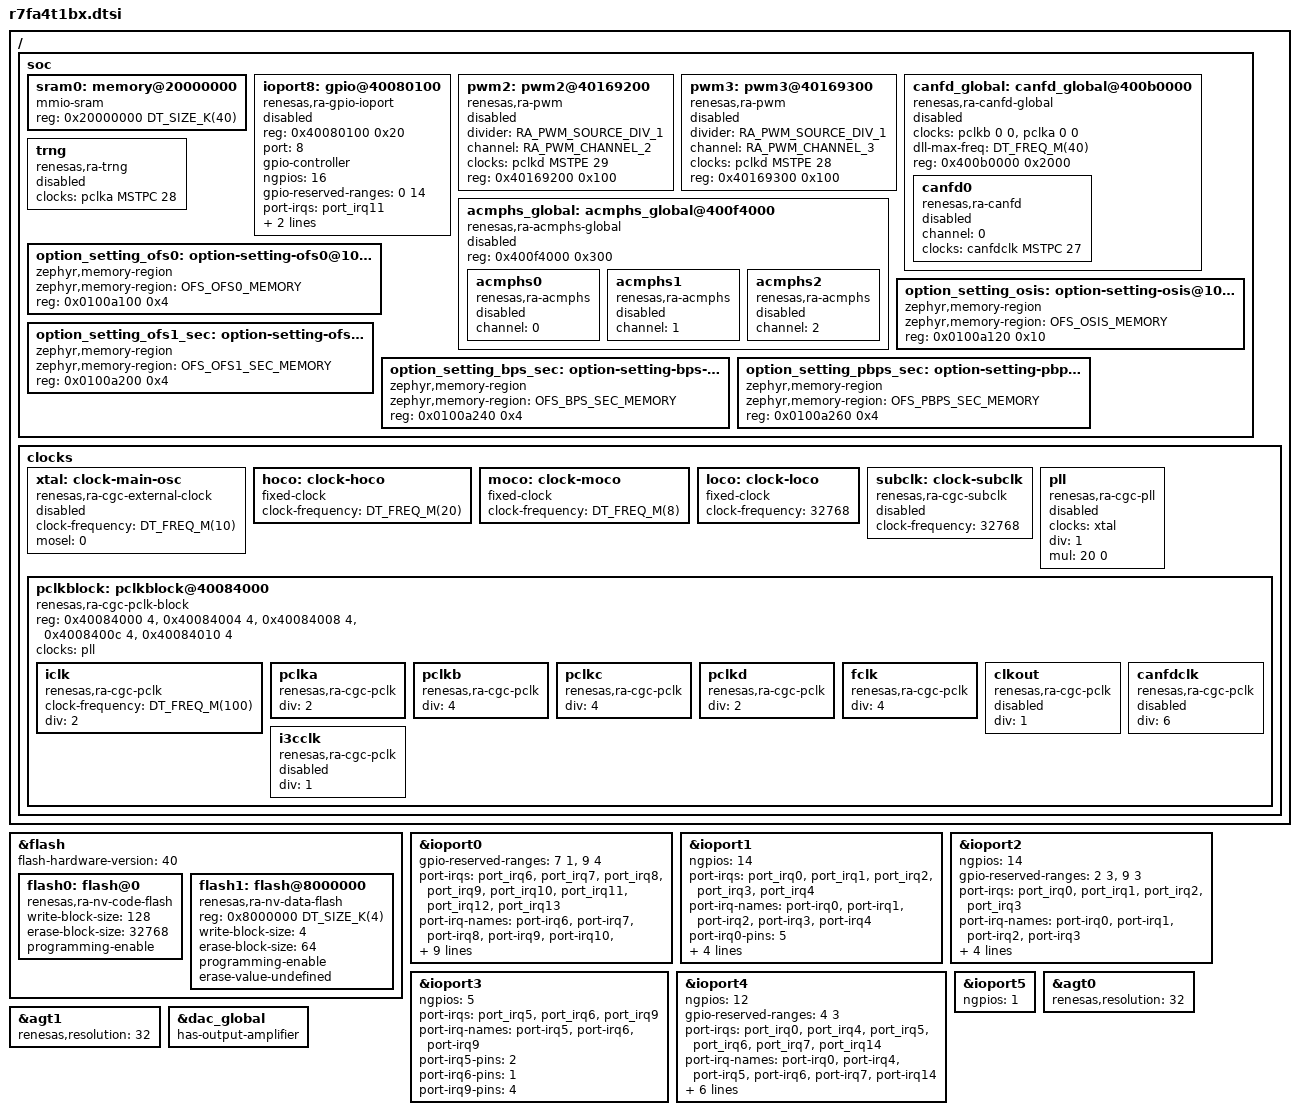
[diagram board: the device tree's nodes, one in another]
/*
 * Copyright (c) 2025 Renesas Electronics Corporation
 *
 * SPDX-License-Identifier: Apache-2.0
 */

#include <arm/renesas/ra/ra4/ra4-cm33-common.dtsi>
#include <zephyr/dt-bindings/misc/renesas/ra-elc/ra4t1-elc.h>

/delete-node/ &iic0;
/delete-node/ &iic1;
/delete-node/ &adc1;
/delete-node/ &agt2;
/delete-node/ &agt3;
/delete-node/ &agt4;
/delete-node/ &agt5;
/delete-node/ &usbfs;
/delete-node/ &usbfs_phy;

/ {
	soc {
		sram0: memory@20000000 {
			compatible = "mmio-sram";
			reg = <0x20000000 DT_SIZE_K(40)>;
		};

		ioport8: gpio@40080100 {
			compatible = "renesas,ra-gpio-ioport";
			reg = <0x40080100 0x20>;
			port = <8>;
			gpio-controller;
			#gpio-cells = <2>;
			ngpios = <16>;
			status = "disabled";
		};

		pwm2: pwm2@40169200 {
			compatible = "renesas,ra-pwm";
			divider = <RA_PWM_SOURCE_DIV_1>;
			channel = <RA_PWM_CHANNEL_2>;
			clocks = <&pclkd MSTPE 29>;
			reg = <0x40169200 0x100>;
			#pwm-cells = <3>;
			status = "disabled";
		};

		pwm3: pwm3@40169300 {
			compatible = "renesas,ra-pwm";
			divider = <RA_PWM_SOURCE_DIV_1>;
			channel = <RA_PWM_CHANNEL_3>;
			clocks = <&pclkd MSTPE 28>;
			reg = <0x40169300 0x100>;
			#pwm-cells = <3>;
			status = "disabled";
		};

		canfd_global: canfd_global@400b0000 {
			compatible = "renesas,ra-canfd-global";
			clocks = <&pclkb 0 0>, <&pclka 0 0>;
			clock-names = "opclk", "ramclk";
			dll-max-freq = <DT_FREQ_M(40)>;
			reg = <0x400b0000 0x2000>;
			status = "disabled";

			canfd0: canfd0 {
				compatible = "renesas,ra-canfd";
				channel = <0>;
				clocks = <&canfdclk MSTPC 27>;
				clock-names = "dllclk";
				status = "disabled";
			};
		};

		acmphs_global: acmphs_global@400f4000 {
			compatible = "renesas,ra-acmphs-global";
			reg = <0x400f4000 0x300>;
			status = "disabled";

			acmphs0: acmphs0 {
				compatible = "renesas,ra-acmphs";
				channel = <0>;
				status = "disabled";
			};

			acmphs1: acmphs1 {
				compatible = "renesas,ra-acmphs";
				channel = <1>;
				status = "disabled";
			};

			acmphs2: acmphs2 {
				compatible = "renesas,ra-acmphs";
				channel = <2>;
				status = "disabled";
			};
		};

		trng: trng {
			compatible = "renesas,ra-trng";
			clocks = <&pclka MSTPC 28>;
			status = "disabled";
		};

		option_setting_ofs0: option-setting-ofs0@100a100 {
			compatible = "zephyr,memory-region";
			zephyr,memory-region = "OFS_OFS0_MEMORY";
			reg = <0x0100a100 0x4>;
			status = "okay";
		};

		option_setting_osis: option-setting-osis@100a120 {
			compatible = "zephyr,memory-region";
			zephyr,memory-region = "OFS_OSIS_MEMORY";
			reg = <0x0100a120 0x10>;
			status = "okay";
		};

		option_setting_ofs1_sec: option-setting-ofs1-sec@100a200 {
			compatible = "zephyr,memory-region";
			zephyr,memory-region = "OFS_OFS1_SEC_MEMORY";
			reg = <0x0100a200 0x4>;
			status = "okay";
		};

		option_setting_bps_sec: option-setting-bps-sec@100a240 {
			compatible = "zephyr,memory-region";
			zephyr,memory-region = "OFS_BPS_SEC_MEMORY";
			reg = <0x0100a240 0x4>;
			status = "okay";
		};

		option_setting_pbps_sec: option-setting-pbps-sec@100a260 {
			compatible = "zephyr,memory-region";
			zephyr,memory-region = "OFS_PBPS_SEC_MEMORY";
			reg = <0x0100a260 0x4>;
			status = "okay";
		};
	};

	clocks: clocks {
		#address-cells = <1>;
		#size-cells = <1>;

		xtal: clock-main-osc {
			compatible = "renesas,ra-cgc-external-clock";
			clock-frequency = <DT_FREQ_M(10)>;
			#clock-cells = <0>;
			mosel = <0>;
			status = "disabled";
		};

		hoco: clock-hoco {
			compatible = "fixed-clock";
			clock-frequency = <DT_FREQ_M(20)>;
			#clock-cells = <0>;
		};

		moco: clock-moco {
			compatible = "fixed-clock";
			clock-frequency = <DT_FREQ_M(8)>;
			#clock-cells = <0>;
		};

		loco: clock-loco {
			compatible = "fixed-clock";
			clock-frequency = <32768>;
			#clock-cells = <0>;
		};

		subclk: clock-subclk {
			compatible = "renesas,ra-cgc-subclk";
			clock-frequency = <32768>;
			#clock-cells = <0>;
			status = "disabled";
		};

		pll: pll {
			compatible = "renesas,ra-cgc-pll";
			#clock-cells = <0>;

			/* PLL */
			clocks = <&xtal>;
			div = <1>;
			mul = <20 0>;
			status = "disabled";
		};

		pclkblock: pclkblock@40084000 {
			compatible = "renesas,ra-cgc-pclk-block";
			reg = <0x40084000 4>, <0x40084004 4>, <0x40084008 4>,
			      <0x4008400c 4>, <0x40084010 4>;
			reg-names = "MSTPA", "MSTPB", "MSTPC",
				    "MSTPD", "MSTPE";
			#clock-cells = <0>;
			clocks = <&pll>;
			status = "okay";

			iclk: iclk {
				compatible = "renesas,ra-cgc-pclk";
				clock-frequency = <DT_FREQ_M(100)>;
				div = <2>;
				#clock-cells = <2>;
				status = "okay";
			};

			pclka: pclka {
				compatible = "renesas,ra-cgc-pclk";
				div = <2>;
				#clock-cells = <2>;
				status = "okay";
			};

			pclkb: pclkb {
				compatible = "renesas,ra-cgc-pclk";
				div = <4>;
				#clock-cells = <2>;
				status = "okay";
			};

			pclkc: pclkc {
				compatible = "renesas,ra-cgc-pclk";
				div = <4>;
				#clock-cells = <2>;
				status = "okay";
			};

			pclkd: pclkd {
				compatible = "renesas,ra-cgc-pclk";
				div = <2>;
				#clock-cells = <2>;
				status = "okay";
			};

			fclk: fclk {
				compatible = "renesas,ra-cgc-pclk";
				div = <4>;
				#clock-cells = <2>;
				status = "okay";
			};

			clkout: clkout {
				compatible = "renesas,ra-cgc-pclk";
				div = <1>;
				#clock-cells = <2>;
				status = "disabled";
			};

			canfdclk: canfdclk {
				compatible = "renesas,ra-cgc-pclk";
				#clock-cells = <2>;
				div = <6>;
				status = "disabled";
			};

			i3cclk: i3cclk {
				compatible = "renesas,ra-cgc-pclk";
				#clock-cells = <2>;
				div = <1>;
				status = "disabled";
			};
		};
	};
};

&flash {
	flash-hardware-version = <40>;
	#erase-block-cells = <2>;

	flash0: flash@0 {
		compatible = "renesas,ra-nv-code-flash";
		write-block-size = <128>;
		erase-block-size = <32768>;
		programming-enable;
	};

	flash1: flash@8000000 {
		compatible = "renesas,ra-nv-data-flash";
		reg = <0x8000000 DT_SIZE_K(4)>;
		write-block-size = <4>;
		erase-block-size = <64>;
		programming-enable;
		erase-value-undefined;
	};
};

&ioport0 {
	gpio-reserved-ranges = <7 1>, <9 4>;
	port-irqs = <&port_irq6 &port_irq7 &port_irq8
		     &port_irq9 &port_irq10 &port_irq11
		     &port_irq12 &port_irq13>;
	port-irq-names = "port-irq6",
			 "port-irq7",
			 "port-irq8",
			 "port-irq9",
			 "port-irq10",
			 "port-irq11",
			 "port-irq12",
			 "port-irq13";
	port-irq6-pins = <0>;
	port-irq7-pins = <1>;
	port-irq8-pins = <2>;
	port-irq9-pins = <4>;
	port-irq10-pins = <5>;
	port-irq11-pins = <6>;
	port-irq12-pins = <8>;
	port-irq13-pins = <15>;
};

&ioport1 {
	ngpios = <14>;
	port-irqs = <&port_irq0 &port_irq1 &port_irq2
		     &port_irq3 &port_irq4>;
	port-irq-names = "port-irq0",
			 "port-irq1",
			 "port-irq2",
			 "port-irq3",
			 "port-irq4";
	port-irq0-pins = <5>;
	port-irq1-pins = <1 4>;
	port-irq2-pins = <0>;
	port-irq3-pins = <10>;
	port-irq4-pins = <11>;
};

&ioport2 {
	ngpios = <14>;
	gpio-reserved-ranges = <2 3>, <9 3>;
	port-irqs = <&port_irq0 &port_irq1 &port_irq2
		     &port_irq3>;
	port-irq-names = "port-irq0",
			 "port-irq1",
			 "port-irq2",
			 "port-irq3";
	port-irq0-pins = <6>;
	port-irq1-pins = <5>;
	port-irq2-pins = <13>;
	port-irq3-pins = <12>;
};

&ioport3 {
	ngpios = <5>;
	port-irqs = <&port_irq5 &port_irq6 &port_irq9>;
	port-irq-names = "port-irq5",
			 "port-irq6",
			 "port-irq9";
	port-irq5-pins = <2>;
	port-irq6-pins = <1>;
	port-irq9-pins = <4>;
};

&ioport4 {
	ngpios = <12>;
	gpio-reserved-ranges = <4 3>;
	port-irqs = <&port_irq0 &port_irq4 &port_irq5
		     &port_irq6 &port_irq7 &port_irq14>;
	port-irq-names = "port-irq0",
			 "port-irq4",
			 "port-irq5",
			 "port-irq6",
			 "port-irq7",
			 "port-irq14";
	port-irq0-pins = <0>;
	port-irq4-pins = <2 11>;
	port-irq5-pins = <1 10>;
	port-irq6-pins = <9>;
	port-irq7-pins = <8>;
	port-irq14-pins = <3>;
};

&ioport5 {
	ngpios = <1>;
};

&ioport8 {
	gpio-reserved-ranges = <0 14>;
	port-irqs = <&port_irq11>;
	port-irq-names = "port-irq11";
	port-irq11-pins = <14>;
};

&agt0 {
	renesas,resolution = <32>;
};

&agt1 {
	renesas,resolution = <32>;
};

&dac_global {
	has-output-amplifier;
};
